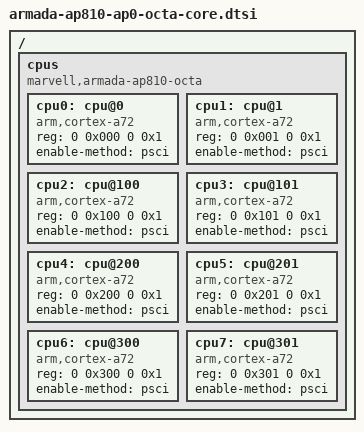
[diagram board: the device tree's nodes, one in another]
// SPDX-License-Identifier: (GPL-2.0+ OR MIT)
/*
 * Copyright (C) 2017 Marvell Technology Group Ltd.
 *
 * Device Tree file for Marvell Armada AP810 OCTA cores.
 */

#include "armada-ap810-ap0.dtsi"

/ {
	cpus {
		#address-cells = <1>;
		#size-cells = <0>;
		compatible = "marvell,armada-ap810-octa";

		cpu0: cpu@0 {
			device_type = "cpu";
			compatible = "arm,cortex-a72";
			reg = <0 0x000 0 0x1>;
			enable-method = "psci";
		};
		cpu1: cpu@1 {
			device_type = "cpu";
			compatible = "arm,cortex-a72";
			reg = <0 0x001 0 0x1>;
			enable-method = "psci";
		};
		cpu2: cpu@100 {
			device_type = "cpu";
			compatible = "arm,cortex-a72";
			reg = <0 0x100 0 0x1>;
			enable-method = "psci";
		};
		cpu3: cpu@101 {
			device_type = "cpu";
			compatible = "arm,cortex-a72";
			reg = <0 0x101 0 0x1>;
			enable-method = "psci";
		};
		cpu4: cpu@200 {
			device_type = "cpu";
			compatible = "arm,cortex-a72";
			reg = <0 0x200 0 0x1>;
			enable-method = "psci";
		};
		cpu5: cpu@201 {
			device_type = "cpu";
			compatible = "arm,cortex-a72";
			reg = <0 0x201 0 0x1>;
			enable-method = "psci";
		};
		cpu6: cpu@300 {
			device_type = "cpu";
			compatible = "arm,cortex-a72";
			reg = <0 0x300 0 0x1>;
			enable-method = "psci";
		};
		cpu7: cpu@301 {
			device_type = "cpu";
			compatible = "arm,cortex-a72";
			reg = <0 0x301 0 0x1>;
			enable-method = "psci";
		};
	};
};
